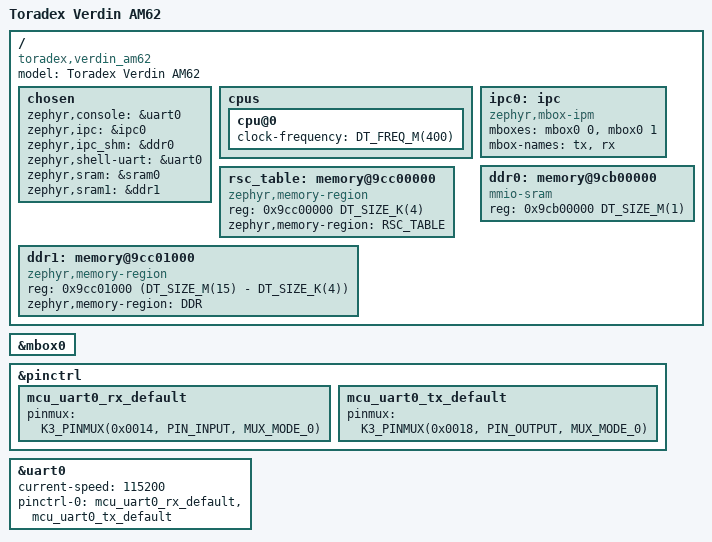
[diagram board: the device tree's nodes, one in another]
/*
 * Copyright (c) 2025 Toradex
 *
 * SPDX-License-Identifier: Apache-2.0
 */

/dts-v1/;

#include <ti/am62x_m4.dtsi>

/ {
	model = "Toradex Verdin AM62";
	compatible = "toradex,verdin_am62";

	chosen {
		zephyr,console = &uart0;
		zephyr,ipc = &ipc0;
		zephyr,ipc_shm = &ddr0;
		zephyr,shell-uart = &uart0;
		zephyr,sram = &sram0;
		zephyr,sram1 = &ddr1;
	};

	cpus {
		cpu@0 {
			clock-frequency = <DT_FREQ_M(400)>;
			status = "okay";
		};
	};

	ipc0: ipc {
		compatible = "zephyr,mbox-ipm";
		mboxes = <&mbox0 0>, <&mbox0 1>;
		mbox-names = "tx", "rx";
	};

	ddr0: memory@9cb00000 {
		compatible = "mmio-sram";
		reg = <0x9cb00000 DT_SIZE_M(1)>;
	};

	rsc_table: memory@9cc00000 {
		compatible = "zephyr,memory-region", "mmio-sram";
		reg = <0x9cc00000 DT_SIZE_K(4)>;
		zephyr,memory-region = "RSC_TABLE";
	};

	ddr1: memory@9cc01000 {
		compatible = "zephyr,memory-region", "mmio-sram";
		reg = <0x9cc01000 (DT_SIZE_M(15) - DT_SIZE_K(4))>;
		zephyr,memory-region = "DDR";
	};
};

&mbox0 {
	status = "okay";
};

&pinctrl {
	mcu_uart0_rx_default: mcu_uart0_rx_default {
		pinmux = <K3_PINMUX(0x0014, PIN_INPUT, MUX_MODE_0)>;
	};

	mcu_uart0_tx_default: mcu_uart0_tx_default {
		pinmux = <K3_PINMUX(0x0018, PIN_OUTPUT, MUX_MODE_0)>;
	};
};

&uart0 {
	current-speed = <115200>;
	pinctrl-0 = <&mcu_uart0_rx_default &mcu_uart0_tx_default>;
	pinctrl-names = "default";
	status = "okay";
};
